# MAX32600 register map
File version: 1.0
ARM 32-bit Cortex-M3 Microcontroller
Registers are 32-bit, read-write, reset 0x0 unless marked. A register's access mark holds for its fields unless they carry their own. Offsets are from the block's base; lines under a group give offsets from that group; [hi:lo] are bit positions; {n}, {i} and the like mark numbered series; 'fields as' and 'values as' point back to an identical list; <NAME> marks a mode.

## Memory map
0x40000000 GPIO size 0x1000 — General Purpose I/O Ports (GPIO)
0x40001000 PTG size 0x8 — Pulse Train Generation
0x40001008 PT0 size 0x8 — Pulse Train Generation
{0x40001008+8n} PT{n} size 0x8 (n=1..15)
0x40010000 CRC size 0x1000 — CRC-16/CRC-32 Engine
0x40011000 TPU size 0x400 — Trust Protection Unit (TPU)
0x40011400 AES size 0x400 — AES Cryptographic Engine
0x40011800 MAA size 0x400 — MAA Cryptographic Engine
0x40011C00 TPU_TSR size 0x400 — Trust Protection Unit (TPU)
0x40012000 TMR0 size 0x1000 — 16/32 bit Timer/Counters
0x40013000 TMR1 size 0x1000
0x40014000 TMR2 size 0x1000
0x40015000 TMR3 size 0x1000
0x40021000 WDT0 size 0x1000 — Watchdog Timers
0x40022000 WDT1 size 0x1000
0x40030000 SPI0 size 0x1000 — SPI Master Interface
0x40031000 SPI1 size 0x1000
0x40032000 SPI2 size 0x1000
0x40038000 UART0 size 0x1000 — UART / Serial Port Interface (Wasp-type)
0x40039000 UART1 size 0x1000
0x40040000 I2CM0 size 0x1000 — I2C Master Interface
0x40041000 I2CS0 size 0x1000 — I2C Slave Interface
0x40042000 I2CM1 size 0x1000
0x40050000 DAC0 size 0x1000 — DAC (DAC0-12bit, DAC1-12bit, DAC2-8bit, DAC3-8bit)
0x40051000 DAC1 size 0x1000
0x40052000 DAC2 size 0x1000
0x40053000 DAC3 size 0x1000
0x40054000 ADC size 0x1C
0x4005401C AFE size 0x1C — Analog Front End Controls
0x40054038 ADCCFG size 0x100 — ADC
0x40070000 PMU0 size 0x20 — Peripheral Management Unit
0x40070020 PMU1 size 0x20
0x40070040 PMU2 size 0x20
0x40070060 PMU3 size 0x20
0x40070080 PMU4 size 0x20
0x400700A0 PMU5 size 0x20
0x40080000 ICC size 0x1000 — Instruction Cache
0x40090400 CLKMAN size 0x400 — System Clock Manager
0x40090800 PWRMAN size 0x200 — System Power Manager
0x40090A00 RTCTMR size 0x30 — Real Time Clock
0x40090A30 PWRSEQ size 0x40 — Power Sequencer
0x40090A70 RTCCFG size 0x90 — Real Time Clock
0x40090C00 IOMAN size 0x400 — System I/O Manager
0x400F0000 FLC size 0x1000 — Flash Controller
0x4010C000 USB size 0x1000 — USB Device Controller

## PTG — Pulse Train Generation
Base 0x40001000
0x00 CTRL — Global Pulse Train Enable/Disable
  [1] enable_all — Enable/disable for all pulse trains
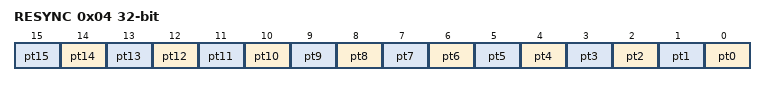
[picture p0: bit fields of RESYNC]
0x04 RESYNC — Global Resync (All Pulse Trains) Control
  [n] pt{n} wo (n=0..15) — Resync control for PT{n}

## PT0 — Pulse Train Generation
Base 0x40001008
Same registers: PT{n} {0x40001008+8n} (n=1..15)
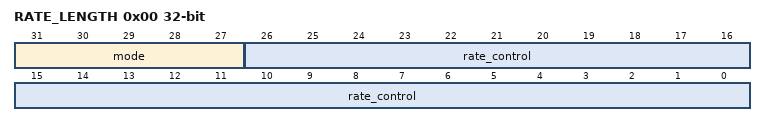
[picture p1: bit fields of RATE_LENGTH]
0x00 RATE_LENGTH — Pulse Train Configuration
  [31:27] mode — Pulse Train Output Mode/Train Length
    0=32_BIT (Pulse train, 32 bit pattern.); 1=SQUARE_WAVE (Square wave mode.); {v}={v}_BIT (Pulse train, {v} bit pattern.) (v=2..9); {v}={v-6}_BIT (Pulse train, {v-6} bit pattern.) (v=16..25); {v}={v-12}_BIT (Pulse train, {v-12} bit pattern.) (v=32..41); 48=30_BIT (Pulse train, 30 bit pattern.); 49=31_BIT (Pulse train, 31 bit pattern.)
  [26:0] rate_control — Pulse Train Enable/Rate Control
0x04 TRAIN — Pulse Train Output Pattern

## CRC — CRC-16/CRC-32 Engine
Base 0x40010000
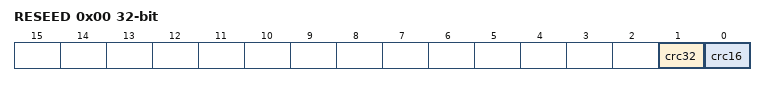
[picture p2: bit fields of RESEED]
0x00 RESEED — CRC-16/CRC-32 Reseed Controls
  [1] crc32 write-1-clears — Reseed CRC32 Generator
  [0] crc16 write-1-clears — Reseed CRC16 Generator
0x04 SEED16 — Reseed Value for CRC-16 Calculations
0x08 SEED32 — Reseed Value for CRC-32 Calculations

## TPU — Trust Protection Unit (TPU)
Base 0x40011000
0x200 PRNG_USER_ENTROPY — PRNG User Entropy Value
0x204 PRNG_RND_NUM — PRNG Random Number Output

## TPU_TSR — Trust Protection Unit (TPU)
Base 0x40011C00
0x00 STATUS — Dynamic Tamper Sensor Status
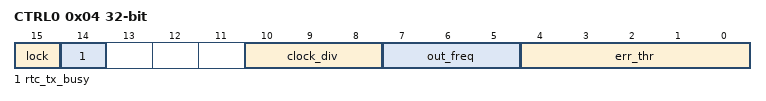
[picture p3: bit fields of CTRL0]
0x04 CTRL0 — Dynamic Tamper Sensor Control 0
  [15] lock — Lock Bit
  [14] rtc_tx_busy ro — RTC Domain Tx Busy
  [10:8] clock_div — Dynamic Sensor Clock Div
  [7:5] out_freq — Dynamic Sensor Output Frequency
  [4:0] err_thr — Dynamic Sensor Error Threshold
0x08 CTRL1 — Dynamic Tamper Sensor Control 1
{0x10+4i} SKS{i} (i=0..3) — TPU Secure Key Storage Register {i} (Cleared on Tamper Detect)
